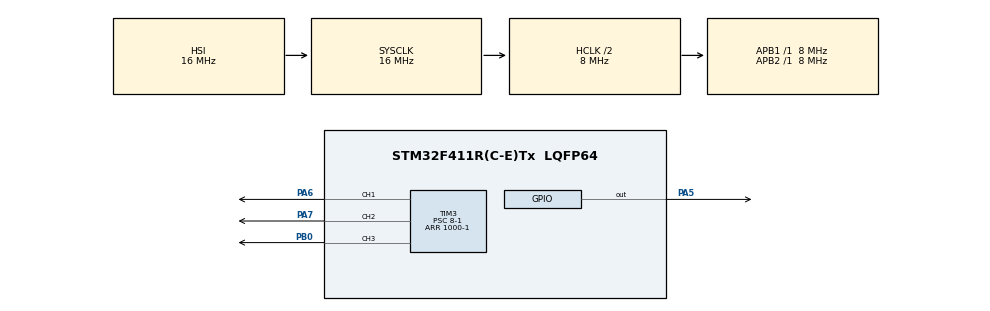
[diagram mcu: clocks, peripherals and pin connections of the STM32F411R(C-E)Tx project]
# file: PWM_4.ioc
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Mcu.Family=STM32F4
Mcu.Name=STM32F411R(C-E)Tx
Mcu.Package=LQFP64
NVIC.PriorityGroup=NVIC_PRIORITYGROUP_0
NVIC.TIM1_UP_TIM10_IRQn=true\:0\:1\:true\:false\:true\:true\:true\:true
PA13.Mode=Serial_Wire
PA13.Signal=SYS_JTMS-SWDIO
PA14.Mode=Serial_Wire
PA14.Signal=SYS_JTCK-SWCLK
PA5.Signal=GPIO_Output
PA6.Signal=S_TIM3_CH1
PA7.Signal=S_TIM3_CH2
PB0.Signal=S_TIM3_CH3
ProjectManager.HeapSize=0x200
ProjectManager.StackSize=0x400
ProjectManager.TargetToolchain=STM32CubeIDE
RCC.48MHZClocksFreq_Value=84000000
RCC.AHBCLKDivider=RCC_SYSCLK_DIV2
RCC.AHBFreq_Value=8000000
RCC.APB1Freq_Value=8000000
RCC.APB1TimFreq_Value=8000000
RCC.APB2Freq_Value=8000000
RCC.APB2TimFreq_Value=8000000
RCC.CortexFreq_Value=8000000
RCC.FLatency-AdvancedSettings=FLASH_LATENCY_0
RCC.HCLKFreq_Value=8000000
RCC.HSE_VALUE=8000000
RCC.HSI_VALUE=16000000
RCC.LSE_VALUE=32768
RCC.PLLN=336
RCC.PLLP=RCC_PLLP_DIV4
RCC.SYSCLKFreq_VALUE=16000000
RCC.VCOOutputFreq_Value=336000000
SH.S_TIM3_CH1.0=TIM3_CH1,PWM Generation1 CH1
SH.S_TIM3_CH2.0=TIM3_CH2,PWM Generation2 CH2
SH.S_TIM3_CH3.0=TIM3_CH3,PWM Generation3 CH3
TIM10.Period=1000-1
TIM10.Prescaler=8000-1
TIM3.Channel-PWM\ Generation1\ CH1=TIM_CHANNEL_1
TIM3.Channel-PWM\ Generation2\ CH2=TIM_CHANNEL_2
TIM3.Channel-PWM\ Generation3\ CH3=TIM_CHANNEL_3
TIM3.Period=1000-1
TIM3.Prescaler=8-1
TIM3.Pulse-PWM\ Generation1\ CH1=1
VP_TIM10_VS_ClockSourceINT.Mode=Enable_Timer
VP_TIM3_VS_ClockSourceINT.Mode=Internal
board=NUCLEO-F411RE

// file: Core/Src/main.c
/* USER CODE BEGIN Header */
/**
  ******************************************************************************
  * @file           : main.c
  * @brief          : Main program body
  ******************************************************************************
  * @attention
  *
  * Copyright (c) 2023 STMicroelectronics.
  * All rights reserved.
  * Este ejercicio tambien se tomo de los videos de calibeta, direccion
  * https://www.youtube.com/watch?v=MrwDeviHgnc&ab_channel=CaliBeta
  * Aqui estamos haciendo un barrido en el PWM del 25% al 100%
  * This software is licensed under terms that can be found in the LICENSE file
  * in the root directory of this software component.
  * If no LICENSE file comes with this software, it is provided AS-IS.
  *
  ******************************************************************************
  */
/* USER CODE END Header */
#include "main.h"

TIM_HandleTypeDef htim3;
TIM_HandleTypeDef htim10;

/* USER CODE BEGIN PV */
uint16_t CicloUtil[3] = {0, 0, 0};
uint16_t CicloUtilMax = 0;
/* USER CODE END PV */

void SystemClock_Config(void);
static void MX_GPIO_Init(void);
static void MX_TIM3_Init(void);
static void MX_TIM10_Init(void);
/* USER CODE BEGIN PFP */
void MaxIlu(TIM_HandleTypeDef *htim3, uint16_t delay, uint8_t led);
void MinIlu(TIM_HandleTypeDef *htim3, uint16_t delay, uint8_t led);
/* USER CODE END PFP */

int main(void)
{

  /* MCU Configuration--------------------------------------------------------*/

  /* Reset of all peripherals, Initializes the Flash interface and the Systick. */
  HAL_Init();

  /* Configure the system clock */
  SystemClock_Config();

  /* Initialize all configured peripherals */
  MX_GPIO_Init();
  MX_TIM3_Init();
  MX_TIM10_Init();
  /* USER CODE BEGIN 2 */
  HAL_TIM_Base_Start_IT(&htim10);
  HAL_TIM_PWM_Start(&htim3, TIM_CHANNEL_1);
  CicloUtilMax = htim3.Instance->ARR; //si hacemos CicloUtil=600 el PWM barre hasta el 60%
  /* USER CODE END 2 */

  /* Infinite loop */
  while (1)
  {

    /* USER CODE BEGIN 3 */
	  //MaxIlu(TIM_HandleTypeDef *htim3, uint16_t delay, uint8_t led);
	  //MinIlu();
  }
  /* USER CODE END 3 */
}
void MaxIlu(TIM_HandleTypeDef *htim3, uint16_t delay, uint8_t led)
{
	for(CicloUtil[led] = 0; CicloUtil[led] < CicloUtilMax; ++CicloUtil[led]){
		switch (led) {
		case 0:
			htim3->Instance->CCR1 = CicloUtil[led];
			break;
		case 1:
			htim3->Instance->CCR2 = CicloUtil[led];
			break;
		case 2:
			htim3->Instance->CCR3 = CicloUtil[led];
			break;
		}
	}
}
//void MinIlu(TIM_HandleTypeDef *htim3, uint16_t delay, uint8_t led);
void SystemClock_Config(void)
{
  RCC_OscInitTypeDef RCC_OscInitStruct = {0};
  RCC_ClkInitTypeDef RCC_ClkInitStruct = {0};

  /** Configure the main internal regulator output voltage
  */
  __HAL_RCC_PWR_CLK_ENABLE();
  __HAL_PWR_VOLTAGESCALING_CONFIG(PWR_REGULATOR_VOLTAGE_SCALE1);

  /** Initializes the RCC Oscillators according to the specified parameters
  * in the RCC_OscInitTypeDef structure.
  */
  RCC_OscInitStruct.OscillatorType = RCC_OSCILLATORTYPE_HSI;
  RCC_OscInitStruct.HSIState = RCC_HSI_ON;
  RCC_OscInitStruct.HSICalibrationValue = RCC_HSICALIBRATION_DEFAULT;
  RCC_OscInitStruct.PLL.PLLState = RCC_PLL_NONE;
  if (HAL_RCC_OscConfig(&RCC_OscInitStruct) != HAL_OK)
  {
    Error_Handler();
  }

  /** Initializes the CPU, AHB and APB buses clocks
  */
  RCC_ClkInitStruct.ClockType = RCC_CLOCKTYPE_HCLK|RCC_CLOCKTYPE_SYSCLK
                              |RCC_CLOCKTYPE_PCLK1|RCC_CLOCKTYPE_PCLK2;
  RCC_ClkInitStruct.SYSCLKSource = RCC_SYSCLKSOURCE_HSI;
  RCC_ClkInitStruct.AHBCLKDivider = RCC_SYSCLK_DIV2;
  RCC_ClkInitStruct.APB1CLKDivider = RCC_HCLK_DIV1;
  RCC_ClkInitStruct.APB2CLKDivider = RCC_HCLK_DIV1;

  if (HAL_RCC_ClockConfig(&RCC_ClkInitStruct, FLASH_LATENCY_0) != HAL_OK)
  {
    Error_Handler();
  }
}

static void MX_TIM3_Init(void)
{

  TIM_ClockConfigTypeDef sClockSourceConfig = {0};
  TIM_MasterConfigTypeDef sMasterConfig = {0};
  TIM_OC_InitTypeDef sConfigOC = {0};

  htim3.Instance = TIM3;
  htim3.Init.Prescaler = 8-1;
  htim3.Init.CounterMode = TIM_COUNTERMODE_UP;
  htim3.Init.Period = 1000-1;
  htim3.Init.ClockDivision = TIM_CLOCKDIVISION_DIV1;
  htim3.Init.AutoReloadPreload = TIM_AUTORELOAD_PRELOAD_DISABLE;
  if (HAL_TIM_Base_Init(&htim3) != HAL_OK)
  {
    Error_Handler();
  }
  sClockSourceConfig.ClockSource = TIM_CLOCKSOURCE_INTERNAL;
  if (HAL_TIM_ConfigClockSource(&htim3, &sClockSourceConfig) != HAL_OK)
  {
    Error_Handler();
  }
  if (HAL_TIM_PWM_Init(&htim3) != HAL_OK)
  {
    Error_Handler();
  }
  sMasterConfig.MasterOutputTrigger = TIM_TRGO_RESET;
  sMasterConfig.MasterSlaveMode = TIM_MASTERSLAVEMODE_DISABLE;
  if (HAL_TIMEx_MasterConfigSynchronization(&htim3, &sMasterConfig) != HAL_OK)
  {
    Error_Handler();
  }
  sConfigOC.OCMode = TIM_OCMODE_PWM1;
  sConfigOC.Pulse = 1;
  sConfigOC.OCPolarity = TIM_OCPOLARITY_HIGH;
  sConfigOC.OCFastMode = TIM_OCFAST_DISABLE;
  if (HAL_TIM_PWM_ConfigChannel(&htim3, &sConfigOC, TIM_CHANNEL_1) != HAL_OK)
  {
    Error_Handler();
  }
  sConfigOC.Pulse = 0;
  if (HAL_TIM_PWM_ConfigChannel(&htim3, &sConfigOC, TIM_CHANNEL_2) != HAL_OK)
  {
    Error_Handler();
  }
  if (HAL_TIM_PWM_ConfigChannel(&htim3, &sConfigOC, TIM_CHANNEL_3) != HAL_OK)
  {
    Error_Handler();
  }
  HAL_TIM_MspPostInit(&htim3);

}

static void MX_TIM10_Init(void)
{

  htim10.Instance = TIM10;
  htim10.Init.Prescaler = 8000-1;
  htim10.Init.CounterMode = TIM_COUNTERMODE_UP;
  htim10.Init.Period = 1000-1;
  htim10.Init.ClockDivision = TIM_CLOCKDIVISION_DIV1;
  htim10.Init.AutoReloadPreload = TIM_AUTORELOAD_PRELOAD_DISABLE;
  if (HAL_TIM_Base_Init(&htim10) != HAL_OK)
  {
    Error_Handler();
  }

}

static void MX_GPIO_Init(void)
{
  GPIO_InitTypeDef GPIO_InitStruct = {0};

  /* GPIO Ports Clock Enable */
  __HAL_RCC_GPIOA_CLK_ENABLE();
  __HAL_RCC_GPIOB_CLK_ENABLE();

  /*Configure GPIO pin Output Level */
  HAL_GPIO_WritePin(GPIOA, GPIO_PIN_5, GPIO_PIN_RESET);

  /*Configure GPIO pin : PA5 */
  GPIO_InitStruct.Pin = GPIO_PIN_5;
  GPIO_InitStruct.Mode = GPIO_MODE_OUTPUT_PP;
  GPIO_InitStruct.Pull = GPIO_NOPULL;
  GPIO_InitStruct.Speed = GPIO_SPEED_FREQ_LOW;
  HAL_GPIO_Init(GPIOA, &GPIO_InitStruct);

}

/* USER CODE BEGIN 4 */
void HAL_TIM_PeriodElapsedCallback(TIM_HandleTypeDef *htim)

{
	if(htim->Instance == TIM10)
	{
		HAL_GPIO_TogglePin(GPIOA, GPIO_PIN_5);
	}
}
/* USER CODE END 4 */

void Error_Handler(void)
{
  __disable_irq();
  while (1)
  {
  }
}
